# EFR32FG25B222F1920IM56 register map
Vendor: Silicon Labs; Series: EFR32; File version: B
Registers are 32-bit, read-write, reset 0x0 unless marked. A register's access mark holds for its fields unless they carry their own. Offsets are from the block's base; [hi:lo] are bit positions; lines under a group give offsets from that group; {n}, {i} and the like mark numbered series; 'fields as' and 'values as' point back to an identical list.

## GPIO_NS — GPIO_NS Registers
Base 0x5003C000
Same registers: GPIO_S 0x4003C000
0x00 IPVERSION ro reset 0x4
  [31:0] IPVERSION — ip version id
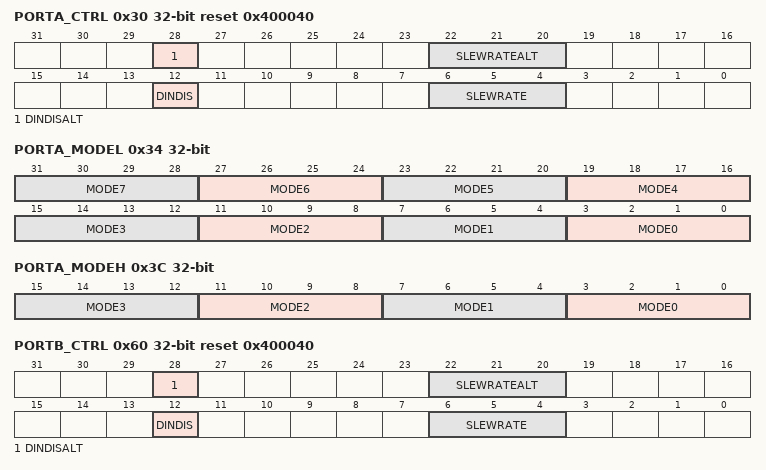
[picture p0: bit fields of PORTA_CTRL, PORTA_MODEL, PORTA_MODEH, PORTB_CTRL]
0x30 PORTA_CTRL reset 0x400040 — Port control
  [28] DINDISALT — Data In Disable Alt
  [22:20] SLEWRATEALT
  [12] DINDIS — Data In Disable
  [6:4] SLEWRATE
0x34 PORTA_MODEL — mode low
  [all] fields
    0=DISABLED (Input disabled. Pullup if DOUT is set.); 1=INPUT (Input enabled. Filter if DOUT is set.); 2=INPUTPULL (Input enabled. DOUT determines pull direction.); 3=INPUTPULLFILTER (Input enabled with filter. DOUT determines pull direction.); 4=PUSHPULL (Push-pull output.); 5=PUSHPULLALT (Push-pull using alternate control.); 6=WIREDOR (Wired-or output.); 7=WIREDORPULLDOWN (Wired-or output with pull-down.); 8=WIREDAND (Open-drain output.); 9=WIREDANDFILTER (Open-drain output with filter.); 10=WIREDANDPULLUP (Open-drain output with pullup.); 11=WIREDANDPULLUPFILTER (Open-drain output with filter and pullup.); 12=WIREDANDALT (Open-drain output using alternate control.); 13=WIREDANDALTFILTER (Open-drain output using alternate control with filter.); 14=WIREDANDALTPULLUP (Open-drain output using alternate control with pullup.); 15=WIREDANDALTPULLUPFILTER (Open-drain output using alternate control with filter and pullup.)
  [4n+3:4n] MODE{n} (n=0..7) — MODE n
0x3C PORTA_MODEH — mode high
  [all] fields
    values as the fields of PORTA_MODEL
  [4n+3:4n] MODE{n} (n=0..3) — MODE n
0x40 PORTA_DOUT — data out
  [11:0] DOUT — Data output
0x44 PORTA_DIN ro — data in
  [11:0] DIN — Data input
0x60 PORTB_CTRL reset 0x400040 — Port control
  fields as PORTA_CTRL
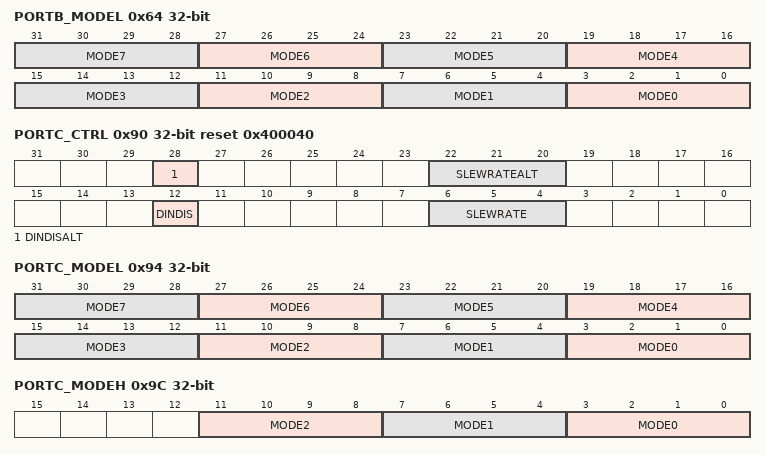
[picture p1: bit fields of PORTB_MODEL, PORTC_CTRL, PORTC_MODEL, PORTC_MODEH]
0x64 PORTB_MODEL — mode low
  fields as PORTA_MODEL
0x6C PORTB_MODEH — mode high
  [3:0] MODE0 — MODE n
    values as the fields of PORTA_MODEL
0x70 PORTB_DOUT — data out
  [8:0] DOUT — Data output
0x74 PORTB_DIN ro — data in
  [8:0] DIN — Data input
0x90 PORTC_CTRL reset 0x400040 — Port control
  fields as PORTA_CTRL
0x94 PORTC_MODEL — mode low
  fields as PORTA_MODEL
0x9C PORTC_MODEH — mode high
  [all] fields
    values as the fields of PORTA_MODEL
  [11:8] MODE2 — MODE n
  [7:4] MODE1 — MODE n
  [3:0] MODE0 — MODE n
0xA0 PORTC_DOUT — data out
  [10:0] DOUT — Data output
0xA4 PORTC_DIN ro — data in
  [10:0] DIN — Data input
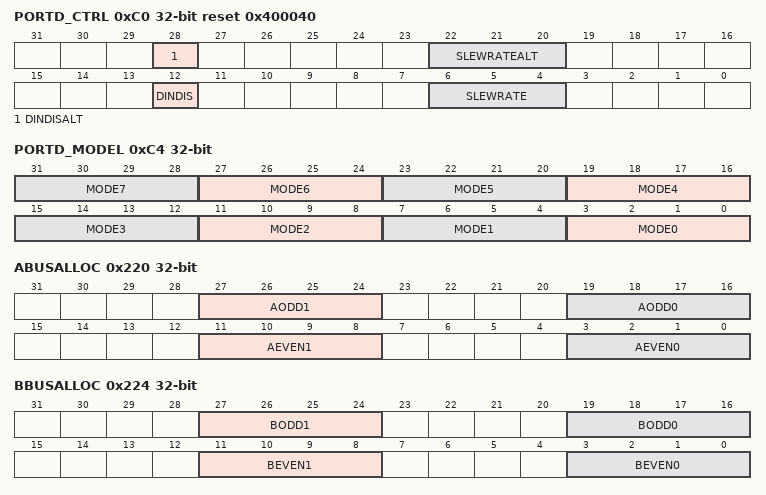
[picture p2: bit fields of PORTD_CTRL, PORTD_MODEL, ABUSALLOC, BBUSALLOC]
0xC0 PORTD_CTRL reset 0x400040 — Port control
  fields as PORTA_CTRL
0xC4 PORTD_MODEL — mode low
  fields as PORTA_MODEL
0xD0 PORTD_DOUT — data out
  [7:0] DOUT — Data output
0xD4 PORTD_DIN ro — data in
  [7:0] DIN — Data input
0x200 LOCK wo reset 0xA534
  [15:0] LOCKKEY — Configuration Lock Key
    0xA534=UNLOCK (Unlock code)
0x210 GPIOLOCKSTATUS ro
  [0] LOCK — GPIO LOCK status
    0=UNLOCKED (Registers are unlocked); 1=LOCKED (Registers are locked)
0x220 ABUSALLOC — A Bus allocation
  [27:24] AODD1 — A Bus Odd 1
    0=TRISTATE (The bus is not allocated); 1=ADC0 (The bus is allocated to ADC0); 2=ACMP0 (The bus is allocated to ACMP0); 3=ACMP1 (The bus is allocated to ACMP1); 4=VDAC0CH1 (The bus is allocated to VDAC0 CH1)
  [19:16] AODD0 — A Bus Odd 0
    0=TRISTATE (The bus is not allocated); 1=ADC0 (The bus is allocated to ADC0); 2=ACMP0 (The bus is allocated to ACMP0); 3=ACMP1 (The bus is allocated to ACMP1); 4=VDAC0CH0 (The bus is allocated to VDAC0 CH0)
  [11:8] AEVEN1 — A Bus Even 1
    values as AODD1
  [3:0] AEVEN0 — A Bus Even 0
    values as AODD0
0x224 BBUSALLOC — B Bus allocation
  [27:24] BODD1 — B Bus Odd 1
    values as ABUSALLOC.AODD1
  [19:16] BODD0 — B Bus Odd 0
    values as ABUSALLOC.AODD0
  [11:8] BEVEN1 — B Bus Even 1
    values as ABUSALLOC.AODD1
  [3:0] BEVEN0 — B Bus Even 0
    values as ABUSALLOC.AODD0
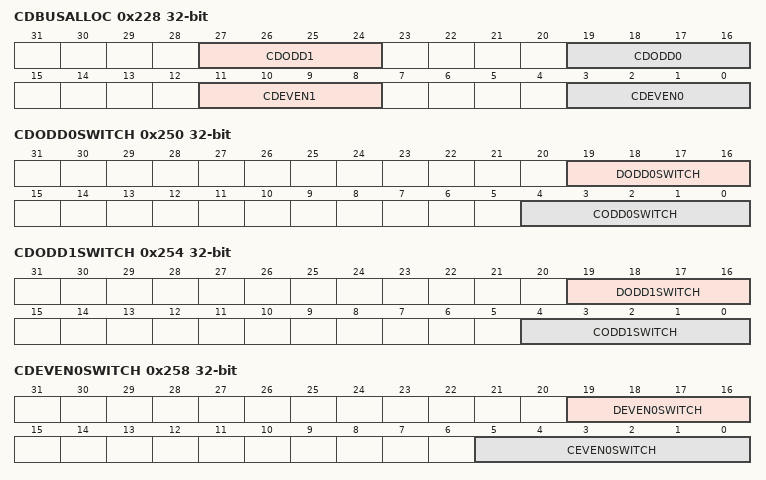
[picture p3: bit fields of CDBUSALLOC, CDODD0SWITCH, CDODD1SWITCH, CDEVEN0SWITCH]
0x228 CDBUSALLOC — CD Bus allocation
  [27:24] CDODD1 — CD Bus Odd 1
    values as ABUSALLOC.AODD1
  [19:16] CDODD0 — CD Bus Odd 0
    values as ABUSALLOC.AODD0
  [11:8] CDEVEN1 — CD Bus Even 1
    values as ABUSALLOC.AODD1
  [3:0] CDEVEN0 — CD Bus Even 0
    values as ABUSALLOC.AODD0
0x230 AODD0SWITCH — ABUS AODD0 Switch Register
  [5:0] AODD0SWITCH
0x234 AODD1SWITCH — ABUS AODD1 Switch Register
  [5:0] AODD1SWITCH
0x238 AEVEN0SWITCH — ABUS AEVEN0 Switch Register
  [5:0] AEVEN0SWITCH
0x23C AEVEN1SWITCH — ABUS AEVEN1 Switch Register
  [5:0] AEVEN1SWITCH
0x240 BODD0SWITCH — ABUS BODD0 Switch Register
  [3:0] BODD0SWITCH — BODD0 Switch Reg
0x244 BODD1SWITCH — ABUS BODD1 Switch Register
  [3:0] BODD1SWITCH — BODD1 Switch Reg
0x248 BEVEN0SWITCH — ABUS BEVEN0 Switch Register
  [4:0] BEVEN0SWITCH
0x24C BEVEN1SWITCH — ABUS BEVEN1 Switch Register
  [4:0] BEVEN1SWITCH
0x250 CDODD0SWITCH — ABUS CDODD0 Switch Register
  [19:16] DODD0SWITCH, [4:0] CODD0SWITCH
0x254 CDODD1SWITCH — ABUS CDODD1 Switch Register
  [19:16] DODD1SWITCH, [4:0] CODD1SWITCH
0x258 CDEVEN0SWITCH — ABUS CDEVEN0 Switch Register
  [19:16] DEVEN0SWITCH, [5:0] CEVEN0SWITCH
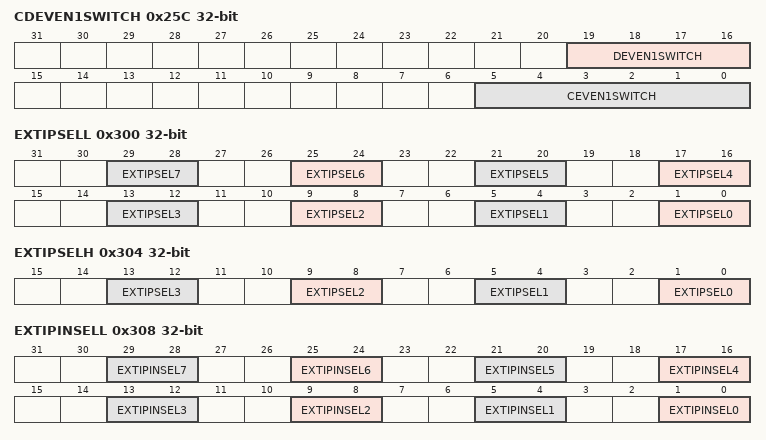
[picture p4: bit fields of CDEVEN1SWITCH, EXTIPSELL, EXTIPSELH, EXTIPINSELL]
0x25C CDEVEN1SWITCH — ABUS CDEVEN1 Switch Register
  [19:16] DEVEN1SWITCH, [5:0] CEVEN1SWITCH
0x300 EXTIPSELL — External Interrupt Port Select Low
  [all] fields
    0=PORTA (Port A group selected); 1=PORTB (Port B group selected); 2=PORTC (Port C group selected); 3=PORTD (Port D group selected)
  [4n+1:4n] EXTIPSEL{n} (n=0..7) — External Interrupt Port Select
0x304 EXTIPSELH — External interrupt Port Select High
  [all] fields
    values as the fields of EXTIPSELL
  [4n+1:4n] EXTIPSEL{n} (n=0..3) — External Interrupt Port Select
0x308 EXTIPINSELL — External Interrupt Pin Select Low
  [all] fields
    {v}=PIN{v} (OFFSET={v}) (v=0..3)
  [4n+1:4n] EXTIPINSEL{n} (n=0..7) — External Interrupt Pin select
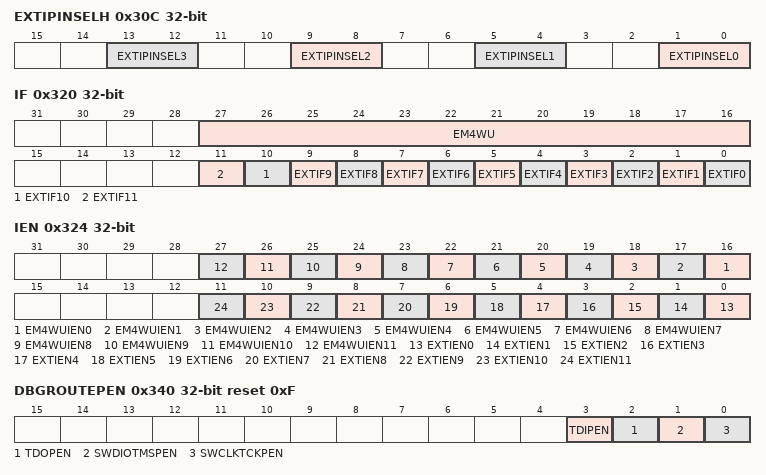
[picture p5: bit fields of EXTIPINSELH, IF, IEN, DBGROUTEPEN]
0x30C EXTIPINSELH — External Interrupt Pin Select High
  [all] fields
    {v}=PIN{v+8} (OFFSET={v+8}) (v=0..3)
  [4n+1:4n] EXTIPINSEL{n} (n=0..3) — External Interrupt Pin select
0x310 EXTIRISE — External Interrupt Rising Edge Trigger
  [11:0] EXTIRISE — EXT Int Rise
0x314 EXTIFALL — External Interrupt Falling Edge Trigger
  [11:0] EXTIFALL — EXT Int FALL
0x320 IF — Interrupt Flag
  [27:16] EM4WU — EM4 wake up
  [n] EXTIF{n} (n=0..11) — External Pin Flag
0x324 IEN — Interrupt Enable
  [n+16] EM4WUIEN{n} (n=0..11) — EM4 Wake Up Interrupt En
  [n] EXTIEN{n} (n=0..11) — External Pin Enable
0x32C EM4WUEN
  [27:16] EM4WUEN — EM4 wake up enable
0x330 EM4WUPOL
  [27:16] EM4WUPOL — EM4 Wake-Up Polarity
0x340 DBGROUTEPEN reset 0xF
  [3] TDIPEN — JTAG Test Debug Input Pin Enable
  [2] TDOPEN — JTAG Test Debug Output Pin Enable
  [1] SWDIOTMSPEN — Route Location 0
  [0] SWCLKTCKPEN — Route Pin Enable
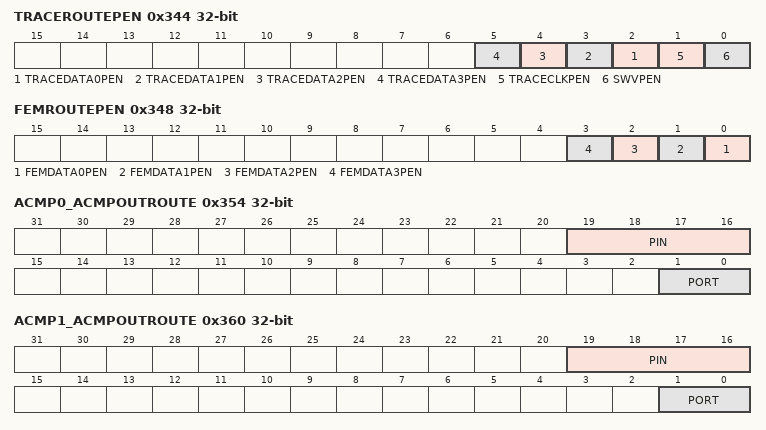
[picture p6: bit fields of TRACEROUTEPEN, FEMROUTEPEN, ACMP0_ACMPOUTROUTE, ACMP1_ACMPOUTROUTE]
0x344 TRACEROUTEPEN
  [n+2] TRACEDATA{n}PEN (n=0..3) — Trace Data{n} Pin Enable
  [1] TRACECLKPEN — Trace Clk Pin Enable
  [0] SWVPEN — Serial Wire Viewer Output Pin Enable
0x348 FEMROUTEPEN
  [n] FEMDATA{n}PEN (n=0..3) — FEM Data{n} Pin Enable
0x350 ACMP0_ROUTEEN — ACMP0 pin enable
  [0] ACMPOUTPEN — ACMPOUT pin enable control bit
0x354 ACMP0_ACMPOUTROUTE — ACMPOUT port/pin select
  [19:16] PIN — ACMPOUT pin select register
  [1:0] PORT — ACMPOUT port select register
0x35C ACMP1_ROUTEEN — ACMP1 pin enable
  [0] ACMPOUTPEN — ACMPOUT pin enable control bit
0x360 ACMP1_ACMPOUTROUTE — ACMPOUT port/pin select
  fields as ACMP0_ACMPOUTROUTE
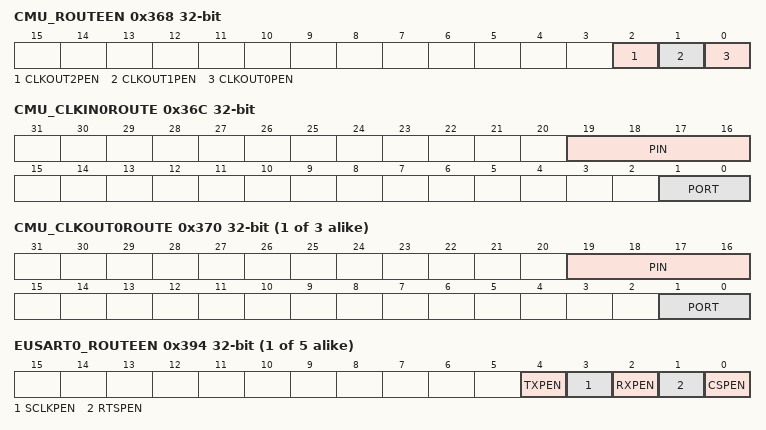
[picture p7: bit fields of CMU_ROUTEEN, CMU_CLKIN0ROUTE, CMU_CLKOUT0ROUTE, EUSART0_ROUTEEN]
0x368 CMU_ROUTEEN — CMU pin enable
  [2] CLKOUT2PEN — CLKOUT2 pin enable control bit
  [1] CLKOUT1PEN — CLKOUT1 pin enable control bit
  [0] CLKOUT0PEN — CLKOUT0 pin enable control bit
0x36C CMU_CLKIN0ROUTE — CLKIN0 port/pin select
  [19:16] PIN — CLKIN0 pin select register
  [1:0] PORT — CLKIN0 port select register
{0x370+4i} CMU_CLKOUT{i}ROUTE (i=0..2) — CLKOUT{i} port/pin select
  [19:16] PIN — CLKOUT{i} pin select register
  [1:0] PORT — CLKOUT{i} port select register
0x384 DCDC_ROUTEEN — DCDC pin enable
  [0] DCDCCOREHIDDENPEN — DCDCCOREHIDDEN pin enable control bit
{0x394+0x20*i} EUSART{i}_ROUTEEN (i=0..4) — EUSART{i} pin enable
  [4] TXPEN — TX pin enable control bit
  [3] SCLKPEN — SCLK pin enable control bit
  [2] RXPEN — RX pin enable control bit
  [1] RTSPEN — RTS pin enable control bit
  [0] CSPEN — CS pin enable control bit
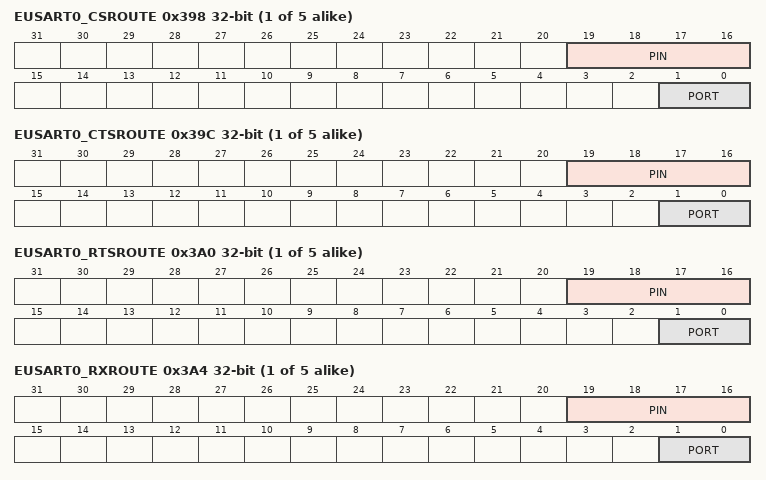
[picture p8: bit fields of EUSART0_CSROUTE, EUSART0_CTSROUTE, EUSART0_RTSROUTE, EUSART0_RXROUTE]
{0x398+0x20*i} EUSART{i}_CSROUTE (i=0..4) — CS port/pin select
  [19:16] PIN — CS pin select register
  [1:0] PORT — CS port select register
{0x39C+0x20*i} EUSART{i}_CTSROUTE (i=0..4) — CTS port/pin select
  [19:16] PIN — CTS pin select register
  [1:0] PORT — CTS port select register
{0x3A0+0x20*i} EUSART{i}_RTSROUTE (i=0..4) — RTS port/pin select
  [19:16] PIN — RTS pin select register
  [1:0] PORT — RTS port select register
{0x3A4+0x20*i} EUSART{i}_RXROUTE (i=0..4) — RX port/pin select
  [19:16] PIN — RX pin select register
  [1:0] PORT — RX port select register
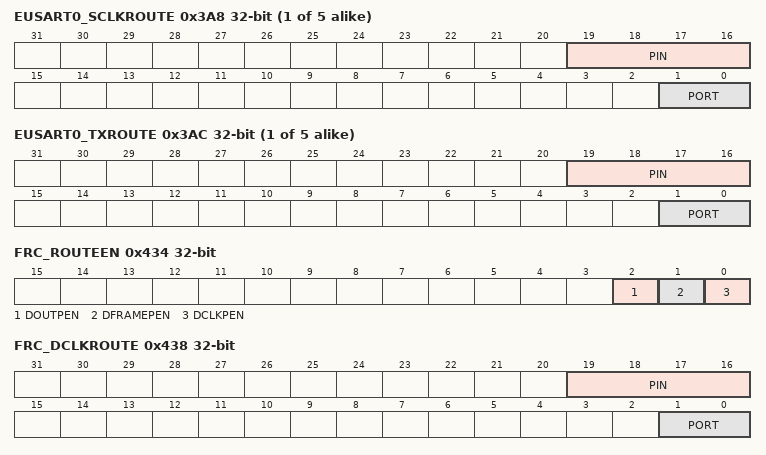
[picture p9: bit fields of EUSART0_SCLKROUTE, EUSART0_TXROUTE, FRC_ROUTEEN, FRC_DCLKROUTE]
{0x3A8+0x20*i} EUSART{i}_SCLKROUTE (i=0..4) — SCLK port/pin select
  [19:16] PIN — SCLK pin select register
  [1:0] PORT — SCLK port select register
{0x3AC+0x20*i} EUSART{i}_TXROUTE (i=0..4) — TX port/pin select
  [19:16] PIN — TX pin select register
  [1:0] PORT — TX port select register
0x434 FRC_ROUTEEN — FRC pin enable
  [2] DOUTPEN — DOUT pin enable control bit
  [1] DFRAMEPEN — DFRAME pin enable control bit
  [0] DCLKPEN — DCLK pin enable control bit
0x438 FRC_DCLKROUTE — DCLK port/pin select
  [19:16] PIN — DCLK pin select register
  [1:0] PORT — DCLK port select register
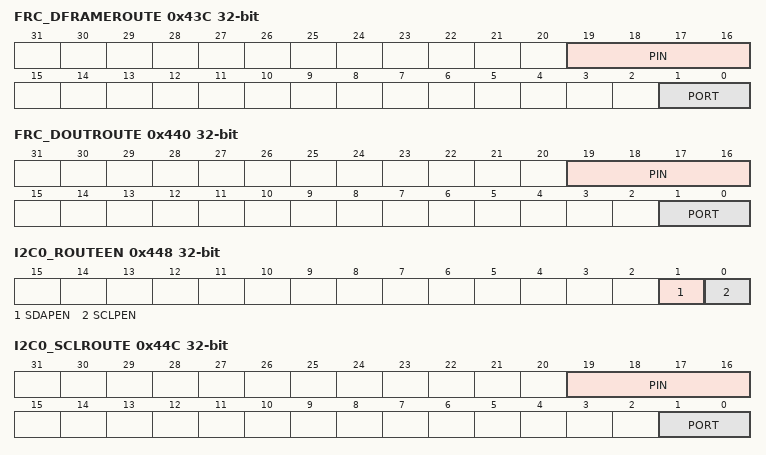
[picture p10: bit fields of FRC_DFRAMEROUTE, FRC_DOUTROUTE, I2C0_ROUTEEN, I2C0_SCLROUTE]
0x43C FRC_DFRAMEROUTE — DFRAME port/pin select
  [19:16] PIN — DFRAME pin select register
  [1:0] PORT — DFRAME port select register
0x440 FRC_DOUTROUTE — DOUT port/pin select
  [19:16] PIN — DOUT pin select register
  [1:0] PORT — DOUT port select register
0x448 I2C0_ROUTEEN — I2C0 pin enable
  [1] SDAPEN — SDA pin enable control bit
  [0] SCLPEN — SCL pin enable control bit
0x44C I2C0_SCLROUTE — SCL port/pin select
  [19:16] PIN — SCL pin select register
  [1:0] PORT — SCL port select register
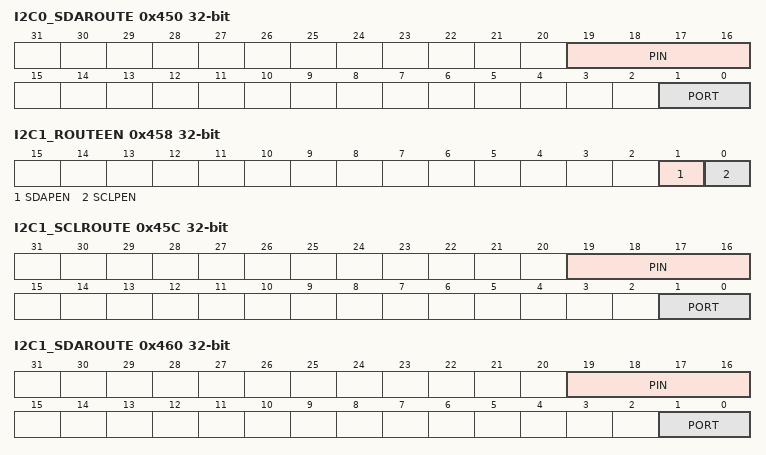
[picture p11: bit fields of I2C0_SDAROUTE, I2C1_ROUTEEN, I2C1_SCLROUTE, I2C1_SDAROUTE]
0x450 I2C0_SDAROUTE — SDA port/pin select
  [19:16] PIN — SDA pin select register
  [1:0] PORT — SDA port select register
0x458 I2C1_ROUTEEN — I2C1 pin enable
  fields as I2C0_ROUTEEN
0x45C I2C1_SCLROUTE — SCL port/pin select
  fields as I2C0_SCLROUTE
0x460 I2C1_SDAROUTE — SDA port/pin select
  fields as I2C0_SDAROUTE
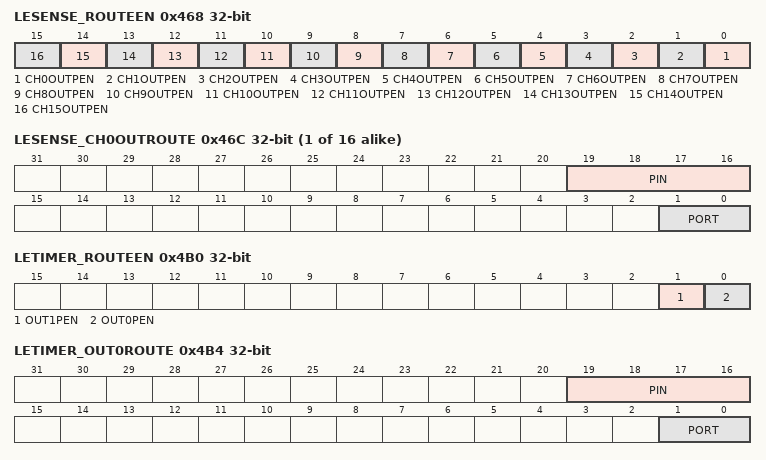
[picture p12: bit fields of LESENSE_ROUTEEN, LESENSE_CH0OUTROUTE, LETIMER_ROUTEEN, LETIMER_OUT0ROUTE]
0x468 LESENSE_ROUTEEN — LESENSE pin enable
  [n] CH{n}OUTPEN (n=0..15) — CH{n}OUT pin enable control bit
{0x46C+4i} LESENSE_CH{i}OUTROUTE (i=0..15) — CH{i}OUT port/pin select
  [19:16] PIN — CH{i}OUT pin select register
  [1:0] PORT — CH{i}OUT port select register
0x4B0 LETIMER_ROUTEEN — LETIMER pin enable
  [1] OUT1PEN — OUT1 pin enable control bit
  [0] OUT0PEN — OUT0 pin enable control bit
0x4B4 LETIMER_OUT0ROUTE — OUT0 port/pin select
  [19:16] PIN — OUT0 pin select register
  [1:0] PORT — OUT0 port select register
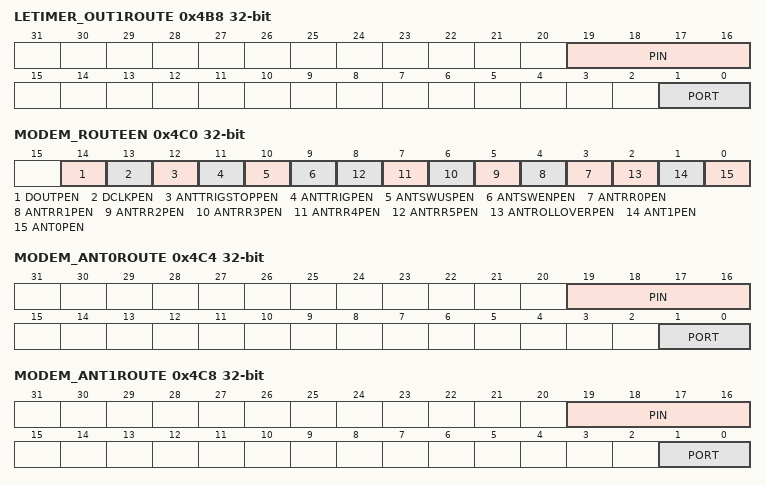
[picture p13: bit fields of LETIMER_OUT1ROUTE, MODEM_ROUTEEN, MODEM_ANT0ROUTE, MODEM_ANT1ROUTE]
0x4B8 LETIMER_OUT1ROUTE — OUT1 port/pin select
  [19:16] PIN — OUT1 pin select register
  [1:0] PORT — OUT1 port select register
0x4C0 MODEM_ROUTEEN — MODEM pin enable
  [14] DOUTPEN — DOUT pin enable control bit
  [13] DCLKPEN — DCLK pin enable control bit
  [12] ANTTRIGSTOPPEN — ANTTRIGSTOP pin enable control bit
  [11] ANTTRIGPEN — ANTTRIG pin enable control bit
  [10] ANTSWUSPEN — ANTSWUS pin enable control bit
  [9] ANTSWENPEN — ANTSWEN pin enable control bit
  [n+3] ANTRR{n}PEN (n=0..5) — ANTRR{n} pin enable control bit
  [2] ANTROLLOVERPEN — ANTROLLOVER pin enable control bit
  [1] ANT1PEN — ANT1 pin enable control bit
  [0] ANT0PEN — ANT0 pin enable control bit
0x4C4 MODEM_ANT0ROUTE — ANT0 port/pin select
  [19:16] PIN — ANT0 pin select register
  [1:0] PORT — ANT0 port select register
0x4C8 MODEM_ANT1ROUTE — ANT1 port/pin select
  [19:16] PIN — ANT1 pin select register
  [1:0] PORT — ANT1 port select register
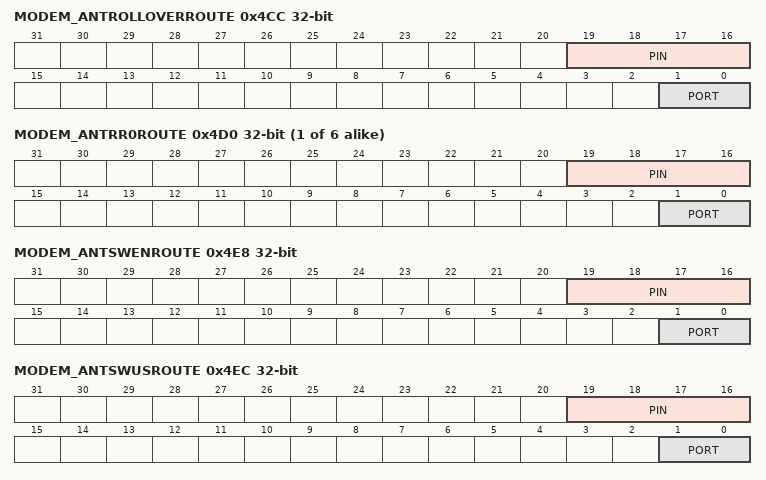
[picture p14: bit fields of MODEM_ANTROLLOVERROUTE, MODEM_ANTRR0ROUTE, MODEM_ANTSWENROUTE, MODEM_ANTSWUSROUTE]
0x4CC MODEM_ANTROLLOVERROUTE — ANTROLLOVER port/pin select
  [19:16] PIN — ANTROLLOVER pin select register
  [1:0] PORT — ANTROLLOVER port select register
{0x4D0+4i} MODEM_ANTRR{i}ROUTE (i=0..5) — ANTRR{i} port/pin select
  [19:16] PIN — ANTRR{i} pin select register
  [1:0] PORT — ANTRR{i} port select register
0x4E8 MODEM_ANTSWENROUTE — ANTSWEN port/pin select
  [19:16] PIN — ANTSWEN pin select register
  [1:0] PORT — ANTSWEN port select register
0x4EC MODEM_ANTSWUSROUTE — ANTSWUS port/pin select
  [19:16] PIN — ANTSWUS pin select register
  [1:0] PORT — ANTSWUS port select register
0x4F0 MODEM_ANTTRIGROUTE — ANTTRIG port/pin select
  [19:16] PIN — ANTTRIG pin select register
  [1:0] PORT — ANTTRIG port select register
0x4F4 MODEM_ANTTRIGSTOPROUTE — ANTTRIGSTOP port/pin select
  [19:16] PIN — ANTTRIGSTOP pin select register
  [1:0] PORT — ANTTRIGSTOP port select register
0x4F8 MODEM_DCLKROUTE — DCLK port/pin select
  fields as FRC_DCLKROUTE
0x4FC MODEM_DINROUTE — DIN port/pin select
  [19:16] PIN — DIN pin select register
  [1:0] PORT — DIN port select register
0x500 MODEM_DOUTROUTE — DOUT port/pin select
  fields as FRC_DOUTROUTE
0x50C PCNT0_S0INROUTE — S0IN port/pin select
  [19:16] PIN — S0IN pin select register
  [1:0] PORT — S0IN port select register
0x510 PCNT0_S1INROUTE — S1IN port/pin select
  [19:16] PIN — S1IN pin select register
  [1:0] PORT — S1IN port select register
0x518 PRS0_ROUTEEN — PRS0 pin enable
  [n+12] SYNCH{n}PEN (n=0..3) — SYNCH{n} pin enable control bit
  [n] ASYNCH{n}PEN (n=0..11) — ASYNCH{n} pin enable control bit
{0x51C+4i} PRS0_ASYNCH{i}ROUTE (i=0..11) — ASYNCH{i} port/pin select
  [19:16] PIN — ASYNCH{i} pin select register
  [1:0] PORT — ASYNCH{i} port select register
{0x54C+4i} PRS0_SYNCH{i}ROUTE (i=0..3) — SYNCH{i} port/pin select
  [19:16] PIN — SYNCH{i} pin select register
  [1:0] PORT — SYNCH{i} port select register
0x5C0 SYXO0_BUFOUTREQINASYNCROUTE — BUFOUTREQINASYNC port/pin select
  [19:16] PIN — BUFOUTREQINASYNC pin select register
  [1:0] PORT — BUFOUTREQINASYNC port select register
{0x5C8+0x20*i} TIMER{i}_ROUTEEN (i=0..7) — TIMER{i} pin enable
  [5] CCC2PEN — CDTI2 pin enable control bit
  [4] CCC1PEN — CDTI1 pin enable control bit
  [3] CCC0PEN — CDTI0 pin enable control bit
  [2] CC2PEN — CC2 pin enable control bit
  [1] CC1PEN — CC1 pin enable control bit
  [0] CC0PEN — CC0 pin enable control bit
{0x5CC+0x20*i} TIMER{i}_CC0ROUTE (i=0..7) — CC0 port/pin select
  [19:16] PIN — CC0 pin select register
  [1:0] PORT — CC0 port select register
{0x5D0+0x20*i} TIMER{i}_CC1ROUTE (i=0..7) — CC1 port/pin select
  [19:16] PIN — CC1 pin select register
  [1:0] PORT — CC1 port select register
{0x5D4+0x20*i} TIMER{i}_CC2ROUTE (i=0..7) — CC2 port/pin select
  [19:16] PIN — CC2 pin select register
  [1:0] PORT — CC2 port select register
{0x5D8+0x20*i} TIMER{i}_CDTI0ROUTE (i=0..7) — CDTI0 port/pin select
  [19:16] PIN — CDTI0 pin select register
  [1:0] PORT — CDTI0 port select register
{0x5DC+0x20*i} TIMER{i}_CDTI1ROUTE (i=0..7) — CDTI1 port/pin select
  [19:16] PIN — CDTI1 pin select register
  [1:0] PORT — CDTI1 port select register
{0x5E0+0x20*i} TIMER{i}_CDTI2ROUTE (i=0..7) — CDTI2 port/pin select
  [19:16] PIN — CDTI2 pin select register
  [1:0] PORT — CDTI2 port select register
0x6CC USB_USBVBUSSENSEROUTE — USBVBUSSENSE port/pin select
  [19:16] PIN — USBVBUSSENSE pin select register
  [1:0] PORT — USBVBUSSENSE port select register
